# MIMXRT1062 register map
Vendor: nxp.com; File version: 1.0
CPU: CM7 r0p1, little endian, MPU, FPU, VTOR, 4 interrupt priority bits
Registers are 32-bit, read-write, reset 0x0 unless marked. A register's access mark holds for its fields unless they carry their own. Offsets are from the block's base; [hi:lo] are bit positions.

## IOMUXC (part 1 of 4)
Base 0x401F8000; register names take the prefix IOMUXC_
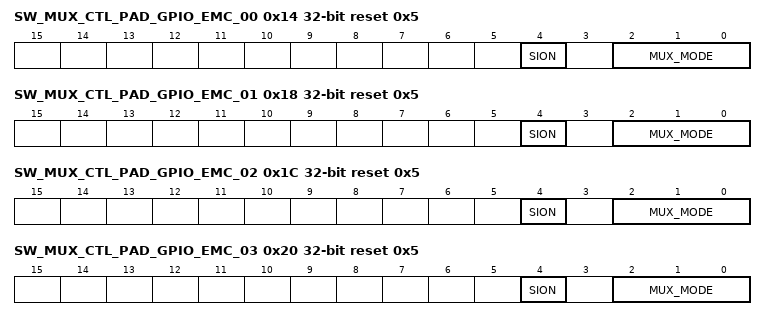
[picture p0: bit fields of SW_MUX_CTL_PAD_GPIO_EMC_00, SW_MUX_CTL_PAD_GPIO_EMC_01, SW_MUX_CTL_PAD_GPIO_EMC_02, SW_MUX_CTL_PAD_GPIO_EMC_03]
0x14 SW_MUX_CTL_PAD_GPIO_EMC_00 reset 0x5 — SW_MUX_CTL_PAD_GPIO_EMC_00 SW MUX Control Register
  [4] SION — Software Input On Field.
    0=DISABLED (Input Path is determined by functionality); 1=ENABLED (Force input path of pad GPIO_EMC_00)
  [2:0] MUX_MODE — MUX Mode Select Field.
    0=ALT0 (Select mux mode: ALT0 mux port: SEMC_DATA00 of instance: semc); 1=ALT1 (Select mux mode: ALT1 mux port: FLEXPWM4_PWMA00 of instance: flexpwm4); 2=ALT2 (Select mux mode: ALT2 mux port: LPSPI2_SCK of instance: lpspi2); 3=ALT3 (Select mux mode: ALT3 mux port: XBAR1_XBAR_IN02 of instance: xbar1); 4=ALT4 (Select mux mode: ALT4 mux port: FLEXIO1_FLEXIO00 of instance: flexio1); 5=ALT5 (Select mux mode: ALT5 mux port: GPIO4_IO00 of instance: gpio4)
0x18 SW_MUX_CTL_PAD_GPIO_EMC_01 reset 0x5 — SW_MUX_CTL_PAD_GPIO_EMC_01 SW MUX Control Register
  [4] SION — Software Input On Field.
    0=DISABLED (Input Path is determined by functionality); 1=ENABLED (Force input path of pad GPIO_EMC_01)
  [2:0] MUX_MODE — MUX Mode Select Field.
    0=ALT0 (Select mux mode: ALT0 mux port: SEMC_DATA01 of instance: semc); 1=ALT1 (Select mux mode: ALT1 mux port: FLEXPWM4_PWMB00 of instance: flexpwm4); 2=ALT2 (Select mux mode: ALT2 mux port: LPSPI2_PCS0 of instance: lpspi2); 3=ALT3 (Select mux mode: ALT3 mux port: XBAR1_IN03 of instance: xbar1); 4=ALT4 (Select mux mode: ALT4 mux port: FLEXIO1_FLEXIO01 of instance: flexio1); 5=ALT5 (Select mux mode: ALT5 mux port: GPIO4_IO01 of instance: gpio4)
0x1C SW_MUX_CTL_PAD_GPIO_EMC_02 reset 0x5 — SW_MUX_CTL_PAD_GPIO_EMC_02 SW MUX Control Register
  [4] SION — Software Input On Field.
    0=DISABLED (Input Path is determined by functionality); 1=ENABLED (Force input path of pad GPIO_EMC_02)
  [2:0] MUX_MODE — MUX Mode Select Field.
    0=ALT0 (Select mux mode: ALT0 mux port: SEMC_DATA02 of instance: semc); 1=ALT1 (Select mux mode: ALT1 mux port: FLEXPWM4_PWMA01 of instance: flexpwm4); 2=ALT2 (Select mux mode: ALT2 mux port: LPSPI2_SDO of instance: lpspi2); 3=ALT3 (Select mux mode: ALT3 mux port: XBAR1_INOUT04 of instance: xbar1); 4=ALT4 (Select mux mode: ALT4 mux port: FLEXIO1_FLEXIO02 of instance: flexio1); 5=ALT5 (Select mux mode: ALT5 mux port: GPIO4_IO02 of instance: gpio4)
0x20 SW_MUX_CTL_PAD_GPIO_EMC_03 reset 0x5 — SW_MUX_CTL_PAD_GPIO_EMC_03 SW MUX Control Register
  [4] SION — Software Input On Field.
    0=DISABLED (Input Path is determined by functionality); 1=ENABLED (Force input path of pad GPIO_EMC_03)
  [2:0] MUX_MODE — MUX Mode Select Field.
    0=ALT0 (Select mux mode: ALT0 mux port: SEMC_DATA03 of instance: semc); 1=ALT1 (Select mux mode: ALT1 mux port: FLEXPWM4_PWMB01 of instance: flexpwm4); 2=ALT2 (Select mux mode: ALT2 mux port: LPSPI2_SDI of instance: lpspi2); 3=ALT3 (Select mux mode: ALT3 mux port: XBAR1_INOUT05 of instance: xbar1); 4=ALT4 (Select mux mode: ALT4 mux port: FLEXIO1_FLEXIO03 of instance: flexio1); 5=ALT5 (Select mux mode: ALT5 mux port: GPIO4_IO03 of instance: gpio4)
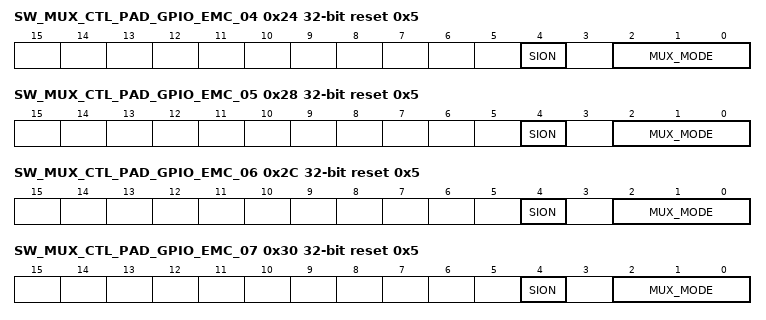
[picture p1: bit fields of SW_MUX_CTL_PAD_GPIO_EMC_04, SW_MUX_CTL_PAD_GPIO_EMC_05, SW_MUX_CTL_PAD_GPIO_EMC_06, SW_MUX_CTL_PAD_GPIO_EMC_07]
0x24 SW_MUX_CTL_PAD_GPIO_EMC_04 reset 0x5 — SW_MUX_CTL_PAD_GPIO_EMC_04 SW MUX Control Register
  [4] SION — Software Input On Field.
    0=DISABLED (Input Path is determined by functionality); 1=ENABLED (Force input path of pad GPIO_EMC_04)
  [2:0] MUX_MODE — MUX Mode Select Field.
    0=ALT0 (Select mux mode: ALT0 mux port: SEMC_DATA04 of instance: semc); 1=ALT1 (Select mux mode: ALT1 mux port: FLEXPWM4_PWMA02 of instance: flexpwm4); 2=ALT2 (Select mux mode: ALT2 mux port: SAI2_TX_DATA of instance: sai2); 3=ALT3 (Select mux mode: ALT3 mux port: XBAR1_INOUT06 of instance: xbar1); 4=ALT4 (Select mux mode: ALT4 mux port: FLEXIO1_FLEXIO04 of instance: flexio1); 5=ALT5 (Select mux mode: ALT5 mux port: GPIO4_IO04 of instance: gpio4)
0x28 SW_MUX_CTL_PAD_GPIO_EMC_05 reset 0x5 — SW_MUX_CTL_PAD_GPIO_EMC_05 SW MUX Control Register
  [4] SION — Software Input On Field.
    0=DISABLED (Input Path is determined by functionality); 1=ENABLED (Force input path of pad GPIO_EMC_05)
  [2:0] MUX_MODE — MUX Mode Select Field.
    0=ALT0 (Select mux mode: ALT0 mux port: SEMC_DATA05 of instance: semc); 1=ALT1 (Select mux mode: ALT1 mux port: FLEXPWM4_PWMB02 of instance: flexpwm4); 2=ALT2 (Select mux mode: ALT2 mux port: SAI2_TX_SYNC of instance: sai2); 3=ALT3 (Select mux mode: ALT3 mux port: XBAR1_INOUT07 of instance: xbar1); 4=ALT4 (Select mux mode: ALT4 mux port: FLEXIO1_FLEXIO05 of instance: flexio1); 5=ALT5 (Select mux mode: ALT5 mux port: GPIO4_IO05 of instance: gpio4)
0x2C SW_MUX_CTL_PAD_GPIO_EMC_06 reset 0x5 — SW_MUX_CTL_PAD_GPIO_EMC_06 SW MUX Control Register
  [4] SION — Software Input On Field.
    0=DISABLED (Input Path is determined by functionality); 1=ENABLED (Force input path of pad GPIO_EMC_06)
  [2:0] MUX_MODE — MUX Mode Select Field.
    0=ALT0 (Select mux mode: ALT0 mux port: SEMC_DATA06 of instance: semc); 1=ALT1 (Select mux mode: ALT1 mux port: FLEXPWM2_PWMA00 of instance: flexpwm2); 2=ALT2 (Select mux mode: ALT2 mux port: SAI2_TX_BCLK of instance: sai2); 3=ALT3 (Select mux mode: ALT3 mux port: XBAR1_INOUT08 of instance: xbar1); 4=ALT4 (Select mux mode: ALT4 mux port: FLEXIO1_FLEXIO06 of instance: flexio1); 5=ALT5 (Select mux mode: ALT5 mux port: GPIO4_IO06 of instance: gpio4)
0x30 SW_MUX_CTL_PAD_GPIO_EMC_07 reset 0x5 — SW_MUX_CTL_PAD_GPIO_EMC_07 SW MUX Control Register
  [4] SION — Software Input On Field.
    0=DISABLED (Input Path is determined by functionality); 1=ENABLED (Force input path of pad GPIO_EMC_07)
  [2:0] MUX_MODE — MUX Mode Select Field.
    0=ALT0 (Select mux mode: ALT0 mux port: SEMC_DATA07 of instance: semc); 1=ALT1 (Select mux mode: ALT1 mux port: FLEXPWM2_PWMB00 of instance: flexpwm2); 2=ALT2 (Select mux mode: ALT2 mux port: SAI2_MCLK of instance: sai2); 3=ALT3 (Select mux mode: ALT3 mux port: XBAR1_INOUT09 of instance: xbar1); 4=ALT4 (Select mux mode: ALT4 mux port: FLEXIO1_FLEXIO07 of instance: flexio1); 5=ALT5 (Select mux mode: ALT5 mux port: GPIO4_IO07 of instance: gpio4)
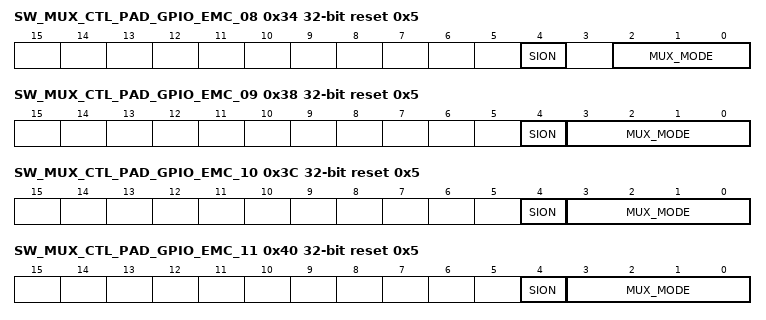
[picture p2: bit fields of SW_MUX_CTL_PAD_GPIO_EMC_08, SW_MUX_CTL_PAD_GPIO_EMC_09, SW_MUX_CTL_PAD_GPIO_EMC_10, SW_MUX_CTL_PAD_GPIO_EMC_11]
0x34 SW_MUX_CTL_PAD_GPIO_EMC_08 reset 0x5 — SW_MUX_CTL_PAD_GPIO_EMC_08 SW MUX Control Register
  [4] SION — Software Input On Field.
    0=DISABLED (Input Path is determined by functionality); 1=ENABLED (Force input path of pad GPIO_EMC_08)
  [2:0] MUX_MODE — MUX Mode Select Field.
    0=ALT0 (Select mux mode: ALT0 mux port: SEMC_DM00 of instance: semc); 1=ALT1 (Select mux mode: ALT1 mux port: FLEXPWM2_PWMA01 of instance: flexpwm2); 2=ALT2 (Select mux mode: ALT2 mux port: SAI2_RX_DATA of instance: sai2); 3=ALT3 (Select mux mode: ALT3 mux port: XBAR1_INOUT17 of instance: xbar1); 4=ALT4 (Select mux mode: ALT4 mux port: FLEXIO1_FLEXIO08 of instance: flexio1); 5=ALT5 (Select mux mode: ALT5 mux port: GPIO4_IO08 of instance: gpio4)
0x38 SW_MUX_CTL_PAD_GPIO_EMC_09 reset 0x5 — SW_MUX_CTL_PAD_GPIO_EMC_09 SW MUX Control Register
  [4] SION — Software Input On Field.
    0=DISABLED (Input Path is determined by functionality); 1=ENABLED (Force input path of pad GPIO_EMC_09)
  [3:0] MUX_MODE — MUX Mode Select Field.
    0=ALT0 (Select mux mode: ALT0 mux port: SEMC_ADDR00 of instance: semc); 1=ALT1 (Select mux mode: ALT1 mux port: FLEXPWM2_PWMB01 of instance: flexpwm2); 2=ALT2 (Select mux mode: ALT2 mux port: SAI2_RX_SYNC of instance: sai2); 3=ALT3 (Select mux mode: ALT3 mux port: FLEXCAN2_TX of instance: flexcan2); 4=ALT4 (Select mux mode: ALT4 mux port: FLEXIO1_FLEXIO09 of instance: flexio1); 5=ALT5 (Select mux mode: ALT5 mux port: GPIO4_IO09 of instance: gpio4); 8=ALT8 (Select mux mode: ALT8 mux port: FLEXSPI2_B_SS1_B of instance: flexspi2)
0x3C SW_MUX_CTL_PAD_GPIO_EMC_10 reset 0x5 — SW_MUX_CTL_PAD_GPIO_EMC_10 SW MUX Control Register
  [4] SION — Software Input On Field.
    0=DISABLED (Input Path is determined by functionality); 1=ENABLED (Force input path of pad GPIO_EMC_10)
  [3:0] MUX_MODE — MUX Mode Select Field.
    0=ALT0 (Select mux mode: ALT0 mux port: SEMC_ADDR01 of instance: semc); 1=ALT1 (Select mux mode: ALT1 mux port: FLEXPWM2_PWMA02 of instance: flexpwm2); 2=ALT2 (Select mux mode: ALT2 mux port: SAI2_RX_BCLK of instance: sai2); 3=ALT3 (Select mux mode: ALT3 mux port: FLEXCAN2_RX of instance: flexcan2); 4=ALT4 (Select mux mode: ALT4 mux port: FLEXIO1_FLEXIO10 of instance: flexio1); 5=ALT5 (Select mux mode: ALT5 mux port: GPIO4_IO10 of instance: gpio4); 8=ALT8 (Select mux mode: ALT8 mux port: FLEXSPI2_B_SS0_B of instance: flexspi2)
0x40 SW_MUX_CTL_PAD_GPIO_EMC_11 reset 0x5 — SW_MUX_CTL_PAD_GPIO_EMC_11 SW MUX Control Register
  [4] SION — Software Input On Field.
    0=DISABLED (Input Path is determined by functionality); 1=ENABLED (Force input path of pad GPIO_EMC_11)
  [3:0] MUX_MODE — MUX Mode Select Field.
    0=ALT0 (Select mux mode: ALT0 mux port: SEMC_ADDR02 of instance: semc); 1=ALT1 (Select mux mode: ALT1 mux port: FLEXPWM2_PWMB02 of instance: flexpwm2); 2=ALT2 (Select mux mode: ALT2 mux port: LPI2C4_SDA of instance: lpi2c4); 3=ALT3 (Select mux mode: ALT3 mux port: USDHC2_RESET_B of instance: usdhc2); 4=ALT4 (Select mux mode: ALT4 mux port: FLEXIO1_FLEXIO11 of instance: flexio1); 5=ALT5 (Select mux mode: ALT5 mux port: GPIO4_IO11 of instance: gpio4); 8=ALT8 (Select mux mode: ALT8 mux port: FLEXSPI2_B_DQS of instance: flexspi2)
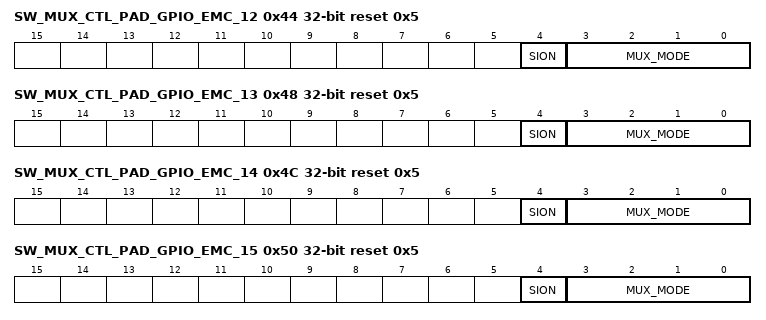
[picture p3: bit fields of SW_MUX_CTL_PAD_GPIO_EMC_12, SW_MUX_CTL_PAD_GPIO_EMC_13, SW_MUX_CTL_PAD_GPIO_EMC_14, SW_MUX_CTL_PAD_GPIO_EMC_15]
0x44 SW_MUX_CTL_PAD_GPIO_EMC_12 reset 0x5 — SW_MUX_CTL_PAD_GPIO_EMC_12 SW MUX Control Register
  [4] SION — Software Input On Field.
    0=DISABLED (Input Path is determined by functionality); 1=ENABLED (Force input path of pad GPIO_EMC_12)
  [3:0] MUX_MODE — MUX Mode Select Field.
    0=ALT0 (Select mux mode: ALT0 mux port: SEMC_ADDR03 of instance: semc); 1=ALT1 (Select mux mode: ALT1 mux port: XBAR1_IN24 of instance: xbar1); 2=ALT2 (Select mux mode: ALT2 mux port: LPI2C4_SCL of instance: lpi2c4); 3=ALT3 (Select mux mode: ALT3 mux port: USDHC1_WP of instance: usdhc1); 4=ALT4 (Select mux mode: ALT4 mux port: FLEXPWM1_PWMA03 of instance: flexpwm1); 5=ALT5 (Select mux mode: ALT5 mux port: GPIO4_IO12 of instance: gpio4); 8=ALT8 (Select mux mode: ALT8 mux port: FLEXSPI2_B_SCLK of instance: flexspi2)
0x48 SW_MUX_CTL_PAD_GPIO_EMC_13 reset 0x5 — SW_MUX_CTL_PAD_GPIO_EMC_13 SW MUX Control Register
  [4] SION — Software Input On Field.
    0=DISABLED (Input Path is determined by functionality); 1=ENABLED (Force input path of pad GPIO_EMC_13)
  [3:0] MUX_MODE — MUX Mode Select Field.
    0=ALT0 (Select mux mode: ALT0 mux port: SEMC_ADDR04 of instance: semc); 1=ALT1 (Select mux mode: ALT1 mux port: XBAR1_IN25 of instance: xbar1); 2=ALT2 (Select mux mode: ALT2 mux port: LPUART3_TX of instance: lpuart3); 3=ALT3 (Select mux mode: ALT3 mux port: MQS_RIGHT of instance: mqs); 4=ALT4 (Select mux mode: ALT4 mux port: FLEXPWM1_PWMB03 of instance: flexpwm1); 5=ALT5 (Select mux mode: ALT5 mux port: GPIO4_IO13 of instance: gpio4); 8=ALT8 (Select mux mode: ALT8 mux port: FLEXSPI2_B_DATA00 of instance: flexspi2)
0x4C SW_MUX_CTL_PAD_GPIO_EMC_14 reset 0x5 — SW_MUX_CTL_PAD_GPIO_EMC_14 SW MUX Control Register
  [4] SION — Software Input On Field.
    0=DISABLED (Input Path is determined by functionality); 1=ENABLED (Force input path of pad GPIO_EMC_14)
  [3:0] MUX_MODE — MUX Mode Select Field.
    0=ALT0 (Select mux mode: ALT0 mux port: SEMC_ADDR05 of instance: semc); 1=ALT1 (Select mux mode: ALT1 mux port: XBAR1_INOUT19 of instance: xbar1); 2=ALT2 (Select mux mode: ALT2 mux port: LPUART3_RX of instance: lpuart3); 3=ALT3 (Select mux mode: ALT3 mux port: MQS_LEFT of instance: mqs); 4=ALT4 (Select mux mode: ALT4 mux port: LPSPI2_PCS1 of instance: lpspi2); 5=ALT5 (Select mux mode: ALT5 mux port: GPIO4_IO14 of instance: gpio4); 8=ALT8 (Select mux mode: ALT8 mux port: FLEXSPI2_B_DATA01 of instance: flexspi2)
0x50 SW_MUX_CTL_PAD_GPIO_EMC_15 reset 0x5 — SW_MUX_CTL_PAD_GPIO_EMC_15 SW MUX Control Register
  [4] SION — Software Input On Field.
    0=DISABLED (Input Path is determined by functionality); 1=ENABLED (Force input path of pad GPIO_EMC_15)
  [3:0] MUX_MODE — MUX Mode Select Field.
    0=ALT0 (Select mux mode: ALT0 mux port: SEMC_ADDR06 of instance: semc); 1=ALT1 (Select mux mode: ALT1 mux port: XBAR1_IN20 of instance: xbar1); 2=ALT2 (Select mux mode: ALT2 mux port: LPUART3_CTS_B of instance: lpuart3); 3=ALT3 (Select mux mode: ALT3 mux port: SPDIF_OUT of instance: spdif); 4=ALT4 (Select mux mode: ALT4 mux port: QTIMER3_TIMER0 of instance: qtimer3); 5=ALT5 (Select mux mode: ALT5 mux port: GPIO4_IO15 of instance: gpio4); 8=ALT8 (Select mux mode: ALT8 mux port: FLEXSPI2_B_DATA02 of instance: flexspi2)
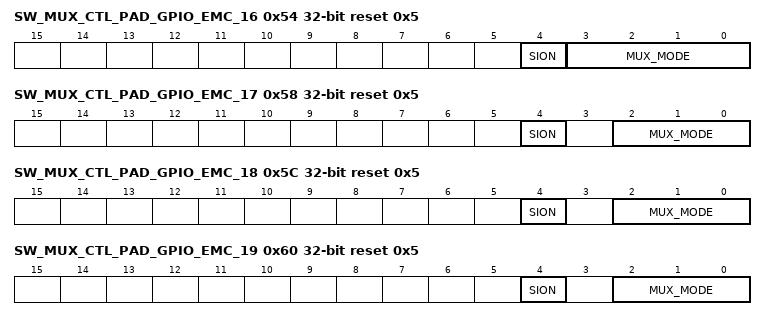
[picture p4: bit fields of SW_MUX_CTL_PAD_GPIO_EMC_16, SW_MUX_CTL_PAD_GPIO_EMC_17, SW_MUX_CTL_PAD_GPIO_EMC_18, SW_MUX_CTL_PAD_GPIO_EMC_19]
0x54 SW_MUX_CTL_PAD_GPIO_EMC_16 reset 0x5 — SW_MUX_CTL_PAD_GPIO_EMC_16 SW MUX Control Register
  [4] SION — Software Input On Field.
    0=DISABLED (Input Path is determined by functionality); 1=ENABLED (Force input path of pad GPIO_EMC_16)
  [3:0] MUX_MODE — MUX Mode Select Field.
    0=ALT0 (Select mux mode: ALT0 mux port: SEMC_ADDR07 of instance: semc); 1=ALT1 (Select mux mode: ALT1 mux port: XBAR1_IN21 of instance: xbar1); 2=ALT2 (Select mux mode: ALT2 mux port: LPUART3_RTS_B of instance: lpuart3); 3=ALT3 (Select mux mode: ALT3 mux port: SPDIF_IN of instance: spdif); 4=ALT4 (Select mux mode: ALT4 mux port: QTIMER3_TIMER1 of instance: qtimer3); 5=ALT5 (Select mux mode: ALT5 mux port: GPIO4_IO16 of instance: gpio4); 8=ALT8 (Select mux mode: ALT8 mux port: FLEXSPI2_B_DATA03 of instance: flexspi2)
0x58 SW_MUX_CTL_PAD_GPIO_EMC_17 reset 0x5 — SW_MUX_CTL_PAD_GPIO_EMC_17 SW MUX Control Register
  [4] SION — Software Input On Field.
    0=DISABLED (Input Path is determined by functionality); 1=ENABLED (Force input path of pad GPIO_EMC_17)
  [2:0] MUX_MODE — MUX Mode Select Field.
    0=ALT0 (Select mux mode: ALT0 mux port: SEMC_ADDR08 of instance: semc); 1=ALT1 (Select mux mode: ALT1 mux port: FLEXPWM4_PWMA03 of instance: flexpwm4); 2=ALT2 (Select mux mode: ALT2 mux port: LPUART4_CTS_B of instance: lpuart4); 3=ALT3 (Select mux mode: ALT3 mux port: FLEXCAN1_TX of instance: flexcan1); 4=ALT4 (Select mux mode: ALT4 mux port: QTIMER3_TIMER2 of instance: qtimer3); 5=ALT5 (Select mux mode: ALT5 mux port: GPIO4_IO17 of instance: gpio4)
0x5C SW_MUX_CTL_PAD_GPIO_EMC_18 reset 0x5 — SW_MUX_CTL_PAD_GPIO_EMC_18 SW MUX Control Register
  [4] SION — Software Input On Field.
    0=DISABLED (Input Path is determined by functionality); 1=ENABLED (Force input path of pad GPIO_EMC_18)
  [2:0] MUX_MODE — MUX Mode Select Field.
    0=ALT0 (Select mux mode: ALT0 mux port: SEMC_ADDR09 of instance: semc); 1=ALT1 (Select mux mode: ALT1 mux port: FLEXPWM4_PWMB03 of instance: flexpwm4); 2=ALT2 (Select mux mode: ALT2 mux port: LPUART4_RTS_B of instance: lpuart4); 3=ALT3 (Select mux mode: ALT3 mux port: FLEXCAN1_RX of instance: flexcan1); 4=ALT4 (Select mux mode: ALT4 mux port: QTIMER3_TIMER3 of instance: qtimer3); 5=ALT5 (Select mux mode: ALT5 mux port: GPIO4_IO18 of instance: gpio4); 6=ALT6 (Select mux mode: ALT6 mux port: SNVS_VIO_5_CTL of instance: snvs_hp)
0x60 SW_MUX_CTL_PAD_GPIO_EMC_19 reset 0x5 — SW_MUX_CTL_PAD_GPIO_EMC_19 SW MUX Control Register
  [4] SION — Software Input On Field.
    0=DISABLED (Input Path is determined by functionality); 1=ENABLED (Force input path of pad GPIO_EMC_19)
  [2:0] MUX_MODE — MUX Mode Select Field.
    0=ALT0 (Select mux mode: ALT0 mux port: SEMC_ADDR11 of instance: semc); 1=ALT1 (Select mux mode: ALT1 mux port: FLEXPWM2_PWMA03 of instance: flexpwm2); 2=ALT2 (Select mux mode: ALT2 mux port: LPUART4_TX of instance: lpuart4); 3=ALT3 (Select mux mode: ALT3 mux port: ENET_RDATA01 of instance: enet); 4=ALT4 (Select mux mode: ALT4 mux port: QTIMER2_TIMER0 of instance: qtimer2); 5=ALT5 (Select mux mode: ALT5 mux port: GPIO4_IO19 of instance: gpio4); 6=ALT6 (Select mux mode: ALT6 mux port: SNVS_VIO_5 of instance: snvs_hp)
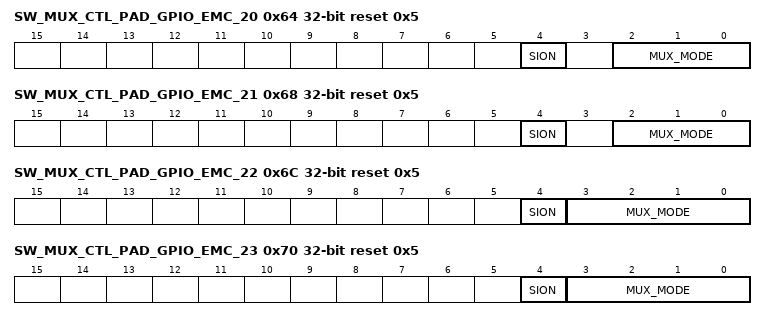
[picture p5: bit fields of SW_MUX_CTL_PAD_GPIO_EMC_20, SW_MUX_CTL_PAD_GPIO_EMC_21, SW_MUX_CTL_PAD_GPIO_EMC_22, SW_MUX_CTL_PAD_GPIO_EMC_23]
0x64 SW_MUX_CTL_PAD_GPIO_EMC_20 reset 0x5 — SW_MUX_CTL_PAD_GPIO_EMC_20 SW MUX Control Register
  [4] SION — Software Input On Field.
    0=DISABLED (Input Path is determined by functionality); 1=ENABLED (Force input path of pad GPIO_EMC_20)
  [2:0] MUX_MODE — MUX Mode Select Field.
    0=ALT0 (Select mux mode: ALT0 mux port: SEMC_ADDR12 of instance: semc); 1=ALT1 (Select mux mode: ALT1 mux port: FLEXPWM2_PWMB03 of instance: flexpwm2); 2=ALT2 (Select mux mode: ALT2 mux port: LPUART4_RX of instance: lpuart4); 3=ALT3 (Select mux mode: ALT3 mux port: ENET_RDATA00 of instance: enet); 4=ALT4 (Select mux mode: ALT4 mux port: QTIMER2_TIMER1 of instance: qtimer2); 5=ALT5 (Select mux mode: ALT5 mux port: GPIO4_IO20 of instance: gpio4)
0x68 SW_MUX_CTL_PAD_GPIO_EMC_21 reset 0x5 — SW_MUX_CTL_PAD_GPIO_EMC_21 SW MUX Control Register
  [4] SION — Software Input On Field.
    0=DISABLED (Input Path is determined by functionality); 1=ENABLED (Force input path of pad GPIO_EMC_21)
  [2:0] MUX_MODE — MUX Mode Select Field.
    0=ALT0 (Select mux mode: ALT0 mux port: SEMC_BA0 of instance: semc); 1=ALT1 (Select mux mode: ALT1 mux port: FLEXPWM3_PWMA03 of instance: flexpwm3); 2=ALT2 (Select mux mode: ALT2 mux port: LPI2C3_SDA of instance: lpi2c3); 3=ALT3 (Select mux mode: ALT3 mux port: ENET_TDATA01 of instance: enet); 4=ALT4 (Select mux mode: ALT4 mux port: QTIMER2_TIMER2 of instance: qtimer2); 5=ALT5 (Select mux mode: ALT5 mux port: GPIO4_IO21 of instance: gpio4)
0x6C SW_MUX_CTL_PAD_GPIO_EMC_22 reset 0x5 — SW_MUX_CTL_PAD_GPIO_EMC_22 SW MUX Control Register
  [4] SION — Software Input On Field.
    0=DISABLED (Input Path is determined by functionality); 1=ENABLED (Force input path of pad GPIO_EMC_22)
  [3:0] MUX_MODE — MUX Mode Select Field.
    0=ALT0 (Select mux mode: ALT0 mux port: SEMC_BA1 of instance: semc); 1=ALT1 (Select mux mode: ALT1 mux port: FLEXPWM3_PWMB03 of instance: flexpwm3); 2=ALT2 (Select mux mode: ALT2 mux port: LPI2C3_SCL of instance: lpi2c3); 3=ALT3 (Select mux mode: ALT3 mux port: ENET_TDATA00 of instance: enet); 4=ALT4 (Select mux mode: ALT4 mux port: QTIMER2_TIMER3 of instance: qtimer2); 5=ALT5 (Select mux mode: ALT5 mux port: GPIO4_IO22 of instance: gpio4); 8=ALT8 (Select mux mode: ALT8 mux port: FLEXSPI2_A_SS1_B of instance: flexspi2)
0x70 SW_MUX_CTL_PAD_GPIO_EMC_23 reset 0x5 — SW_MUX_CTL_PAD_GPIO_EMC_23 SW MUX Control Register
  [4] SION — Software Input On Field.
    0=DISABLED (Input Path is determined by functionality); 1=ENABLED (Force input path of pad GPIO_EMC_23)
  [3:0] MUX_MODE — MUX Mode Select Field.
    0=ALT0 (Select mux mode: ALT0 mux port: SEMC_ADDR10 of instance: semc); 1=ALT1 (Select mux mode: ALT1 mux port: FLEXPWM1_PWMA00 of instance: flexpwm1); 2=ALT2 (Select mux mode: ALT2 mux port: LPUART5_TX of instance: lpuart5); 3=ALT3 (Select mux mode: ALT3 mux port: ENET_RX_EN of instance: enet); 4=ALT4 (Select mux mode: ALT4 mux port: GPT1_CAPTURE2 of instance: gpt1); 5=ALT5 (Select mux mode: ALT5 mux port: GPIO4_IO23 of instance: gpio4); 8=ALT8 (Select mux mode: ALT8 mux port: FLEXSPI2_A_DQS of instance: flexspi2)
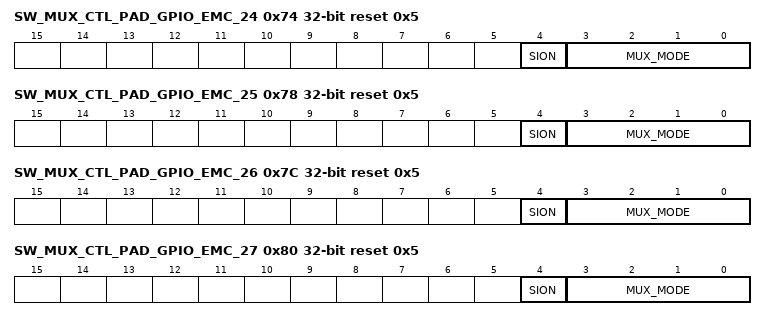
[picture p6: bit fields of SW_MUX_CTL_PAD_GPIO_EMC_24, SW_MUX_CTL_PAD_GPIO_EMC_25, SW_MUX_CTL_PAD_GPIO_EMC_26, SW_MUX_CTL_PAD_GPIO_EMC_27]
0x74 SW_MUX_CTL_PAD_GPIO_EMC_24 reset 0x5 — SW_MUX_CTL_PAD_GPIO_EMC_24 SW MUX Control Register
  [4] SION — Software Input On Field.
    0=DISABLED (Input Path is determined by functionality); 1=ENABLED (Force input path of pad GPIO_EMC_24)
  [3:0] MUX_MODE — MUX Mode Select Field.
    0=ALT0 (Select mux mode: ALT0 mux port: SEMC_CAS of instance: semc); 1=ALT1 (Select mux mode: ALT1 mux port: FLEXPWM1_PWMB00 of instance: flexpwm1); 2=ALT2 (Select mux mode: ALT2 mux port: LPUART5_RX of instance: lpuart5); 3=ALT3 (Select mux mode: ALT3 mux port: ENET_TX_EN of instance: enet); 4=ALT4 (Select mux mode: ALT4 mux port: GPT1_CAPTURE1 of instance: gpt1); 5=ALT5 (Select mux mode: ALT5 mux port: GPIO4_IO24 of instance: gpio4); 8=ALT8 (Select mux mode: ALT8 mux port: FLEXSPI2_A_SS0_B of instance: flexspi2)
0x78 SW_MUX_CTL_PAD_GPIO_EMC_25 reset 0x5 — SW_MUX_CTL_PAD_GPIO_EMC_25 SW MUX Control Register
  [4] SION — Software Input On Field.
    0=DISABLED (Input Path is determined by functionality); 1=ENABLED (Force input path of pad GPIO_EMC_25)
  [3:0] MUX_MODE — MUX Mode Select Field.
    0=ALT0 (Select mux mode: ALT0 mux port: SEMC_RAS of instance: semc); 1=ALT1 (Select mux mode: ALT1 mux port: FLEXPWM1_PWMA01 of instance: flexpwm1); 2=ALT2 (Select mux mode: ALT2 mux port: LPUART6_TX of instance: lpuart6); 3=ALT3 (Select mux mode: ALT3 mux port: ENET_TX_CLK of instance: enet); 4=ALT4 (Select mux mode: ALT4 mux port: ENET_REF_CLK of instance: enet); 5=ALT5 (Select mux mode: ALT5 mux port: GPIO4_IO25 of instance: gpio4); 8=ALT8 (Select mux mode: ALT8 mux port: FLEXSPI2_A_SCLK of instance: flexspi2)
0x7C SW_MUX_CTL_PAD_GPIO_EMC_26 reset 0x5 — SW_MUX_CTL_PAD_GPIO_EMC_26 SW MUX Control Register
  [4] SION — Software Input On Field.
    0=DISABLED (Input Path is determined by functionality); 1=ENABLED (Force input path of pad GPIO_EMC_26)
  [3:0] MUX_MODE — MUX Mode Select Field.
    0=ALT0 (Select mux mode: ALT0 mux port: SEMC_CLK of instance: semc); 1=ALT1 (Select mux mode: ALT1 mux port: FLEXPWM1_PWMB01 of instance: flexpwm1); 2=ALT2 (Select mux mode: ALT2 mux port: LPUART6_RX of instance: lpuart6); 3=ALT3 (Select mux mode: ALT3 mux port: ENET_RX_ER of instance: enet); 4=ALT4 (Select mux mode: ALT4 mux port: FLEXIO1_FLEXIO12 of instance: flexio1); 5=ALT5 (Select mux mode: ALT5 mux port: GPIO4_IO26 of instance: gpio4); 8=ALT8 (Select mux mode: ALT8 mux port: FLEXSPI2_A_DATA00 of instance: flexspi2)
0x80 SW_MUX_CTL_PAD_GPIO_EMC_27 reset 0x5 — SW_MUX_CTL_PAD_GPIO_EMC_27 SW MUX Control Register
  [4] SION — Software Input On Field.
    0=DISABLED (Input Path is determined by functionality); 1=ENABLED (Force input path of pad GPIO_EMC_27)
  [3:0] MUX_MODE — MUX Mode Select Field.
    0=ALT0 (Select mux mode: ALT0 mux port: SEMC_CKE of instance: semc); 1=ALT1 (Select mux mode: ALT1 mux port: FLEXPWM1_PWMA02 of instance: flexpwm1); 2=ALT2 (Select mux mode: ALT2 mux port: LPUART5_RTS_B of instance: lpuart5); 3=ALT3 (Select mux mode: ALT3 mux port: LPSPI1_SCK of instance: lpspi1); 4=ALT4 (Select mux mode: ALT4 mux port: FLEXIO1_FLEXIO13 of instance: flexio1); 5=ALT5 (Select mux mode: ALT5 mux port: GPIO4_IO27 of instance: gpio4); 8=ALT8 (Select mux mode: ALT8 mux port: FLEXSPI2_A_DATA01 of instance: flexspi2)
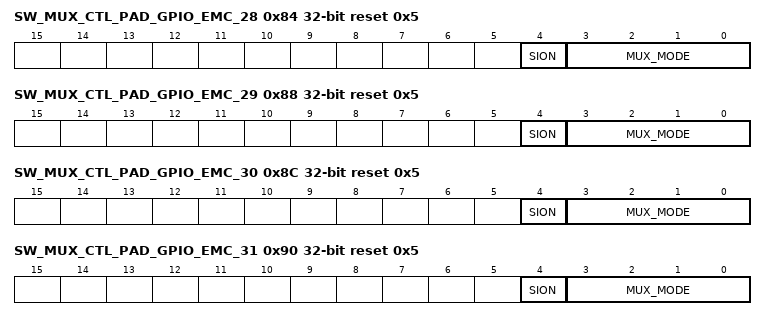
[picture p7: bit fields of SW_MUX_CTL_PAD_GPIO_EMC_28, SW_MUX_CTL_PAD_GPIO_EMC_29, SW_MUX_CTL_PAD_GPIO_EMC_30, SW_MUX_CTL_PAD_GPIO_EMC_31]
0x84 SW_MUX_CTL_PAD_GPIO_EMC_28 reset 0x5 — SW_MUX_CTL_PAD_GPIO_EMC_28 SW MUX Control Register
  [4] SION — Software Input On Field.
    0=DISABLED (Input Path is determined by functionality); 1=ENABLED (Force input path of pad GPIO_EMC_28)
  [3:0] MUX_MODE — MUX Mode Select Field.
    0=ALT0 (Select mux mode: ALT0 mux port: SEMC_WE of instance: semc); 1=ALT1 (Select mux mode: ALT1 mux port: FLEXPWM1_PWMB02 of instance: flexpwm1); 2=ALT2 (Select mux mode: ALT2 mux port: LPUART5_CTS_B of instance: lpuart5); 3=ALT3 (Select mux mode: ALT3 mux port: LPSPI1_SDO of instance: lpspi1); 4=ALT4 (Select mux mode: ALT4 mux port: FLEXIO1_FLEXIO14 of instance: flexio1); 5=ALT5 (Select mux mode: ALT5 mux port: GPIO4_IO28 of instance: gpio4); 8=ALT8 (Select mux mode: ALT8 mux port: FLEXSPI2_A_DATA02 of instance: flexspi2)
0x88 SW_MUX_CTL_PAD_GPIO_EMC_29 reset 0x5 — SW_MUX_CTL_PAD_GPIO_EMC_29 SW MUX Control Register
  [4] SION — Software Input On Field.
    0=DISABLED (Input Path is determined by functionality); 1=ENABLED (Force input path of pad GPIO_EMC_29)
  [3:0] MUX_MODE — MUX Mode Select Field.
    0=ALT0 (Select mux mode: ALT0 mux port: SEMC_CS0 of instance: semc); 1=ALT1 (Select mux mode: ALT1 mux port: FLEXPWM3_PWMA00 of instance: flexpwm3); 2=ALT2 (Select mux mode: ALT2 mux port: LPUART6_RTS_B of instance: lpuart6); 3=ALT3 (Select mux mode: ALT3 mux port: LPSPI1_SDI of instance: lpspi1); 4=ALT4 (Select mux mode: ALT4 mux port: FLEXIO1_FLEXIO15 of instance: flexio1); 5=ALT5 (Select mux mode: ALT5 mux port: GPIO4_IO29 of instance: gpio4); 8=ALT8 (Select mux mode: ALT8 mux port: FLEXSPI2_A_DATA03 of instance: flexspi2)
0x8C SW_MUX_CTL_PAD_GPIO_EMC_30 reset 0x5 — SW_MUX_CTL_PAD_GPIO_EMC_30 SW MUX Control Register
  [4] SION — Software Input On Field.
    0=DISABLED (Input Path is determined by functionality); 1=ENABLED (Force input path of pad GPIO_EMC_30)
  [3:0] MUX_MODE — MUX Mode Select Field.
    0=ALT0 (Select mux mode: ALT0 mux port: SEMC_DATA08 of instance: semc); 1=ALT1 (Select mux mode: ALT1 mux port: FLEXPWM3_PWMB00 of instance: flexpwm3); 2=ALT2 (Select mux mode: ALT2 mux port: LPUART6_CTS_B of instance: lpuart6); 3=ALT3 (Select mux mode: ALT3 mux port: LPSPI1_PCS0 of instance: lpspi1); 4=ALT4 (Select mux mode: ALT4 mux port: CSI_DATA23 of instance: csi); 5=ALT5 (Select mux mode: ALT5 mux port: GPIO4_IO30 of instance: gpio4); 8=ALT8 (Select mux mode: ALT8 mux port: ENET2_TDATA00 of instance: enet2)
0x90 SW_MUX_CTL_PAD_GPIO_EMC_31 reset 0x5 — SW_MUX_CTL_PAD_GPIO_EMC_31 SW MUX Control Register
  [4] SION — Software Input On Field.
    0=DISABLED (Input Path is determined by functionality); 1=ENABLED (Force input path of pad GPIO_EMC_31)
  [3:0] MUX_MODE — MUX Mode Select Field.
    0=ALT0 (Select mux mode: ALT0 mux port: SEMC_DATA09 of instance: semc); 1=ALT1 (Select mux mode: ALT1 mux port: FLEXPWM3_PWMA01 of instance: flexpwm3); 2=ALT2 (Select mux mode: ALT2 mux port: LPUART7_TX of instance: lpuart7); 3=ALT3 (Select mux mode: ALT3 mux port: LPSPI1_PCS1 of instance: lpspi1); 4=ALT4 (Select mux mode: ALT4 mux port: CSI_DATA22 of instance: csi); 5=ALT5 (Select mux mode: ALT5 mux port: GPIO4_IO31 of instance: gpio4); 8=ALT8 (Select mux mode: ALT8 mux port: ENET2_TDATA01 of instance: enet2)
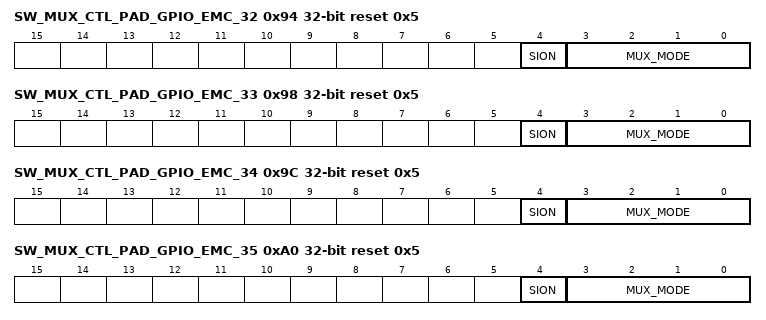
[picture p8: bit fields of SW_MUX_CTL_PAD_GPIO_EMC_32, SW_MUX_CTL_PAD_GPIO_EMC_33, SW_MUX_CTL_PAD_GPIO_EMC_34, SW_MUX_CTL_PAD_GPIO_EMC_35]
0x94 SW_MUX_CTL_PAD_GPIO_EMC_32 reset 0x5 — SW_MUX_CTL_PAD_GPIO_EMC_32 SW MUX Control Register
  [4] SION — Software Input On Field.
    0=DISABLED (Input Path is determined by functionality); 1=ENABLED (Force input path of pad GPIO_EMC_32)
  [3:0] MUX_MODE — MUX Mode Select Field.
    0=ALT0 (Select mux mode: ALT0 mux port: SEMC_DATA10 of instance: semc); 1=ALT1 (Select mux mode: ALT1 mux port: FLEXPWM3_PWMB01 of instance: flexpwm3); 2=ALT2 (Select mux mode: ALT2 mux port: LPUART7_RX of instance: lpuart7); 3=ALT3 (Select mux mode: ALT3 mux port: CCM_PMIC_RDY of instance: ccm); 4=ALT4 (Select mux mode: ALT4 mux port: CSI_DATA21 of instance: csi); 5=ALT5 (Select mux mode: ALT5 mux port: GPIO3_IO18 of instance: gpio3); 8=ALT8 (Select mux mode: ALT8 mux port: ENET2_TX_EN of instance: enet2)
0x98 SW_MUX_CTL_PAD_GPIO_EMC_33 reset 0x5 — SW_MUX_CTL_PAD_GPIO_EMC_33 SW MUX Control Register
  [4] SION — Software Input On Field.
    0=DISABLED (Input Path is determined by functionality); 1=ENABLED (Force input path of pad GPIO_EMC_33)
  [3:0] MUX_MODE — MUX Mode Select Field.
    0=ALT0 (Select mux mode: ALT0 mux port: SEMC_DATA11 of instance: semc); 1=ALT1 (Select mux mode: ALT1 mux port: FLEXPWM3_PWMA02 of instance: flexpwm3); 2=ALT2 (Select mux mode: ALT2 mux port: USDHC1_RESET_B of instance: usdhc1); 3=ALT3 (Select mux mode: ALT3 mux port: SAI3_RX_DATA of instance: sai3); 4=ALT4 (Select mux mode: ALT4 mux port: CSI_DATA20 of instance: csi); 5=ALT5 (Select mux mode: ALT5 mux port: GPIO3_IO19 of instance: gpio3); 8=ALT8 (Select mux mode: ALT8 mux port: ENET2_TX_CLK of instance: enet2); 9=ALT9 (Select mux mode: ALT9 mux port: ENET2_REF_CLK2 of instance: enet2)
0x9C SW_MUX_CTL_PAD_GPIO_EMC_34 reset 0x5 — SW_MUX_CTL_PAD_GPIO_EMC_34 SW MUX Control Register
  [4] SION — Software Input On Field.
    0=DISABLED (Input Path is determined by functionality); 1=ENABLED (Force input path of pad GPIO_EMC_34)
  [3:0] MUX_MODE — MUX Mode Select Field.
    0=ALT0 (Select mux mode: ALT0 mux port: SEMC_DATA12 of instance: semc); 1=ALT1 (Select mux mode: ALT1 mux port: FLEXPWM3_PWMB02 of instance: flexpwm3); 2=ALT2 (Select mux mode: ALT2 mux port: USDHC1_VSELECT of instance: usdhc1); 3=ALT3 (Select mux mode: ALT3 mux port: SAI3_RX_SYNC of instance: sai3); 4=ALT4 (Select mux mode: ALT4 mux port: CSI_DATA19 of instance: csi); 5=ALT5 (Select mux mode: ALT5 mux port: GPIO3_IO20 of instance: gpio3); 8=ALT8 (Select mux mode: ALT8 mux port: ENET2_RX_ER of instance: enet2)
0xA0 SW_MUX_CTL_PAD_GPIO_EMC_35 reset 0x5 — SW_MUX_CTL_PAD_GPIO_EMC_35 SW MUX Control Register
  [4] SION — Software Input On Field.
    0=DISABLED (Input Path is determined by functionality); 1=ENABLED (Force input path of pad GPIO_EMC_35)
  [3:0] MUX_MODE — MUX Mode Select Field.
    0=ALT0 (Select mux mode: ALT0 mux port: SEMC_DATA13 of instance: semc); 1=ALT1 (Select mux mode: ALT1 mux port: XBAR1_INOUT18 of instance: xbar1); 2=ALT2 (Select mux mode: ALT2 mux port: GPT1_COMPARE1 of instance: gpt1); 3=ALT3 (Select mux mode: ALT3 mux port: SAI3_RX_BCLK of instance: sai3); 4=ALT4 (Select mux mode: ALT4 mux port: CSI_DATA18 of instance: csi); 5=ALT5 (Select mux mode: ALT5 mux port: GPIO3_IO21 of instance: gpio3); 6=ALT6 (Select mux mode: ALT6 mux port: USDHC1_CD_B of instance: usdhc1); 8=ALT8 (Select mux mode: ALT8 mux port: ENET2_RDATA00 of instance: enet2)
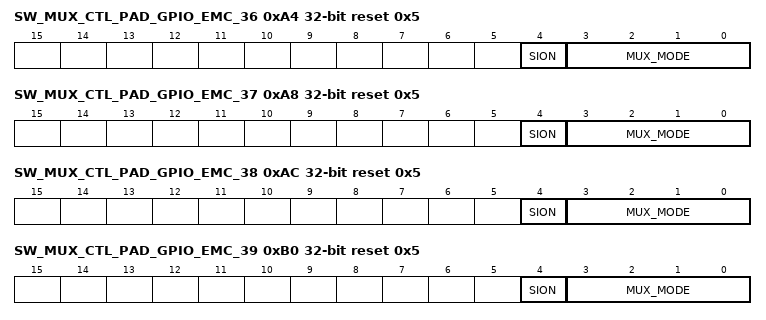
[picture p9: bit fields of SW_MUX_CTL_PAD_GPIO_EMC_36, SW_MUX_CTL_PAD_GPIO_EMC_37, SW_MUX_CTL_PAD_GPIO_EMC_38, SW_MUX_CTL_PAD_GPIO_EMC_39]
0xA4 SW_MUX_CTL_PAD_GPIO_EMC_36 reset 0x5 — SW_MUX_CTL_PAD_GPIO_EMC_36 SW MUX Control Register
  [4] SION — Software Input On Field.
    0=DISABLED (Input Path is determined by functionality); 1=ENABLED (Force input path of pad GPIO_EMC_36)
  [3:0] MUX_MODE — MUX Mode Select Field.
    0=ALT0 (Select mux mode: ALT0 mux port: SEMC_DATA14 of instance: semc); 1=ALT1 (Select mux mode: ALT1 mux port: XBAR1_IN22 of instance: xbar1); 2=ALT2 (Select mux mode: ALT2 mux port: GPT1_COMPARE2 of instance: gpt1); 3=ALT3 (Select mux mode: ALT3 mux port: SAI3_TX_DATA of instance: sai3); 4=ALT4 (Select mux mode: ALT4 mux port: CSI_DATA17 of instance: csi); 5=ALT5 (Select mux mode: ALT5 mux port: GPIO3_IO22 of instance: gpio3); 6=ALT6 (Select mux mode: ALT6 mux port: USDHC1_WP of instance: usdhc1); 8=ALT8 (Select mux mode: ALT8 mux port: ENET2_RDATA01 of instance: enet2); 9=ALT9 (Select mux mode: ALT9 mux port: FLEXCAN3_TX of instance: flexcan3/canfd)
0xA8 SW_MUX_CTL_PAD_GPIO_EMC_37 reset 0x5 — SW_MUX_CTL_PAD_GPIO_EMC_37 SW MUX Control Register
  [4] SION — Software Input On Field.
    0=DISABLED (Input Path is determined by functionality); 1=ENABLED (Force input path of pad GPIO_EMC_37)
  [3:0] MUX_MODE — MUX Mode Select Field.
    0=ALT0 (Select mux mode: ALT0 mux port: SEMC_DATA15 of instance: semc); 1=ALT1 (Select mux mode: ALT1 mux port: XBAR1_IN23 of instance: xbar1); 2=ALT2 (Select mux mode: ALT2 mux port: GPT1_COMPARE3 of instance: gpt1); 3=ALT3 (Select mux mode: ALT3 mux port: SAI3_MCLK of instance: sai3); 4=ALT4 (Select mux mode: ALT4 mux port: CSI_DATA16 of instance: csi); 5=ALT5 (Select mux mode: ALT5 mux port: GPIO3_IO23 of instance: gpio3); 6=ALT6 (Select mux mode: ALT6 mux port: USDHC2_WP of instance: usdhc2); 8=ALT8 (Select mux mode: ALT8 mux port: ENET2_RX_EN of instance: enet2); 9=ALT9 (Select mux mode: ALT9 mux port: FLEXCAN3_RX of instance: flexcan3/canfd)
0xAC SW_MUX_CTL_PAD_GPIO_EMC_38 reset 0x5 — SW_MUX_CTL_PAD_GPIO_EMC_38 SW MUX Control Register
  [4] SION — Software Input On Field.
    0=DISABLED (Input Path is determined by functionality); 1=ENABLED (Force input path of pad GPIO_EMC_38)
  [3:0] MUX_MODE — MUX Mode Select Field.
    0=ALT0 (Select mux mode: ALT0 mux port: SEMC_DM01 of instance: semc); 1=ALT1 (Select mux mode: ALT1 mux port: FLEXPWM1_PWMA03 of instance: flexpwm1); 2=ALT2 (Select mux mode: ALT2 mux port: LPUART8_TX of instance: lpuart8); 3=ALT3 (Select mux mode: ALT3 mux port: SAI3_TX_BCLK of instance: sai3); 4=ALT4 (Select mux mode: ALT4 mux port: CSI_FIELD of instance: csi); 5=ALT5 (Select mux mode: ALT5 mux port: GPIO3_IO24 of instance: gpio3); 6=ALT6 (Select mux mode: ALT6 mux port: USDHC2_VSELECT of instance: usdhc2); 8=ALT8 (Select mux mode: ALT8 mux port: ENET2_MDC of instance: enet2)
0xB0 SW_MUX_CTL_PAD_GPIO_EMC_39 reset 0x5 — SW_MUX_CTL_PAD_GPIO_EMC_39 SW MUX Control Register
  [4] SION — Software Input On Field.
    0=DISABLED (Input Path is determined by functionality); 1=ENABLED (Force input path of pad GPIO_EMC_39)
  [3:0] MUX_MODE — MUX Mode Select Field.
    0=ALT0 (Select mux mode: ALT0 mux port: SEMC_DQS of instance: semc); 1=ALT1 (Select mux mode: ALT1 mux port: FLEXPWM1_PWMB03 of instance: flexpwm1); 2=ALT2 (Select mux mode: ALT2 mux port: LPUART8_RX of instance: lpuart8); 3=ALT3 (Select mux mode: ALT3 mux port: SAI3_TX_SYNC of instance: sai3); 4=ALT4 (Select mux mode: ALT4 mux port: WDOG1_WDOG_B of instance: wdog1); 5=ALT5 (Select mux mode: ALT5 mux port: GPIO3_IO25 of instance: gpio3); 6=ALT6 (Select mux mode: ALT6 mux port: USDHC2_CD_B of instance: usdhc2); 8=ALT8 (Select mux mode: ALT8 mux port: ENET2_MDIO of instance: enet2); 9=ALT9 (Select mux mode: ALT9 mux port: SEMC_DQS4 of instance: semc)
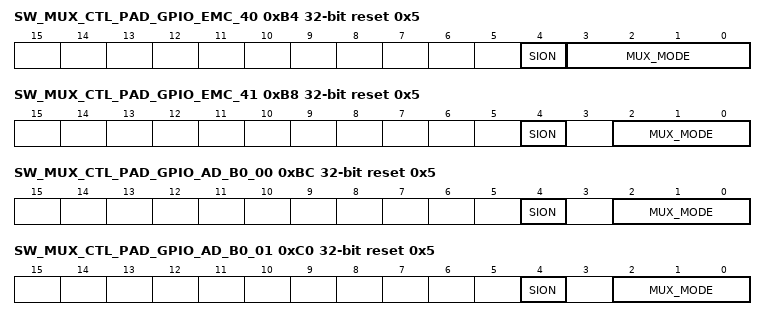
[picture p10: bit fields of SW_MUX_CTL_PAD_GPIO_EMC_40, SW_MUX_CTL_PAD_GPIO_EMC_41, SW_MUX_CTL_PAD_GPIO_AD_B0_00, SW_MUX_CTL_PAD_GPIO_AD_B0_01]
0xB4 SW_MUX_CTL_PAD_GPIO_EMC_40 reset 0x5 — SW_MUX_CTL_PAD_GPIO_EMC_40 SW MUX Control Register
  [4] SION — Software Input On Field.
    0=DISABLED (Input Path is determined by functionality); 1=ENABLED (Force input path of pad GPIO_EMC_40)
  [3:0] MUX_MODE — MUX Mode Select Field.
    0=ALT0 (Select mux mode: ALT0 mux port: SEMC_RDY of instance: semc); 1=ALT1 (Select mux mode: ALT1 mux port: GPT2_CAPTURE2 of instance: gpt2); 2=ALT2 (Select mux mode: ALT2 mux port: LPSPI1_PCS2 of instance: lpspi1); 3=ALT3 (Select mux mode: ALT3 mux port: USB_OTG2_OC of instance: usb); 4=ALT4 (Select mux mode: ALT4 mux port: ENET_MDC of instance: enet); 5=ALT5 (Select mux mode: ALT5 mux port: GPIO3_IO26 of instance: gpio3); 6=ALT6 (Select mux mode: ALT6 mux port: USDHC2_RESET_B of instance: usdhc2); 9=ALT9 (Select mux mode: ALT9 mux port: SEMC_CLK5 of instance: semc)
0xB8 SW_MUX_CTL_PAD_GPIO_EMC_41 reset 0x5 — SW_MUX_CTL_PAD_GPIO_EMC_41 SW MUX Control Register
  [4] SION — Software Input On Field.
    0=DISABLED (Input Path is determined by functionality); 1=ENABLED (Force input path of pad GPIO_EMC_41)
  [2:0] MUX_MODE — MUX Mode Select Field.
    0=ALT0 (Select mux mode: ALT0 mux port: SEMC_CSX00 of instance: semc); 1=ALT1 (Select mux mode: ALT1 mux port: GPT2_CAPTURE1 of instance: gpt2); 2=ALT2 (Select mux mode: ALT2 mux port: LPSPI1_PCS3 of instance: lpspi1); 3=ALT3 (Select mux mode: ALT3 mux port: USB_OTG2_PWR of instance: usb); 4=ALT4 (Select mux mode: ALT4 mux port: ENET_MDIO of instance: enet); 5=ALT5 (Select mux mode: ALT5 mux port: GPIO3_IO27 of instance: gpio3); 6=ALT6 (Select mux mode: ALT6 mux port: USDHC1_VSELECT of instance: usdhc1)
0xBC SW_MUX_CTL_PAD_GPIO_AD_B0_00 reset 0x5 — SW_MUX_CTL_PAD_GPIO_AD_B0_00 SW MUX Control Register
  [4] SION — Software Input On Field.
    0=DISABLED (Input Path is determined by functionality); 1=ENABLED (Force input path of pad GPIO_AD_B0_00)
  [2:0] MUX_MODE — MUX Mode Select Field.
    0=ALT0 (Select mux mode: ALT0 mux port: FLEXPWM2_PWMA03 of instance: flexpwm2); 1=ALT1 (Select mux mode: ALT1 mux port: XBAR1_INOUT14 of instance: xbar1); 2=ALT2 (Select mux mode: ALT2 mux port: REF_CLK_32K of instance: xtalosc); 3=ALT3 (Select mux mode: ALT3 mux port: USB_OTG2_ID of instance: usb); 4=ALT4 (Select mux mode: ALT4 mux port: LPI2C1_SCLS of instance: lpi2c1); 5=ALT5 (Select mux mode: ALT5 mux port: GPIO1_IO00 of instance: gpio1); 6=ALT6 (Select mux mode: ALT6 mux port: USDHC1_RESET_B of instance: usdhc1); 7=ALT7 (Select mux mode: ALT7 mux port: LPSPI3_SCK of instance: lpspi3)
0xC0 SW_MUX_CTL_PAD_GPIO_AD_B0_01 reset 0x5 — SW_MUX_CTL_PAD_GPIO_AD_B0_01 SW MUX Control Register
  [4] SION — Software Input On Field.
    0=DISABLED (Input Path is determined by functionality); 1=ENABLED (Force input path of pad GPIO_AD_B0_01)
  [2:0] MUX_MODE — MUX Mode Select Field.
    0=ALT0 (Select mux mode: ALT0 mux port: FLEXPWM2_PWMB03 of instance: flexpwm2); 1=ALT1 (Select mux mode: ALT1 mux port: XBAR1_INOUT15 of instance: xbar1); 2=ALT2 (Select mux mode: ALT2 mux port: REF_CLK_24M of instance: anatop); 3=ALT3 (Select mux mode: ALT3 mux port: USB_OTG1_ID of instance: anatop); 4=ALT4 (Select mux mode: ALT4 mux port: LPI2C1_SDAS of instance: lpi2c1); 5=ALT5 (Select mux mode: ALT5 mux port: GPIO1_IO01 of instance: gpio1); 6=ALT6 (Select mux mode: ALT6 mux port: EWM_OUT_B of instance: ewm); 7=ALT7 (Select mux mode: ALT7 mux port: LPSPI3_SDO of instance: lpspi3)
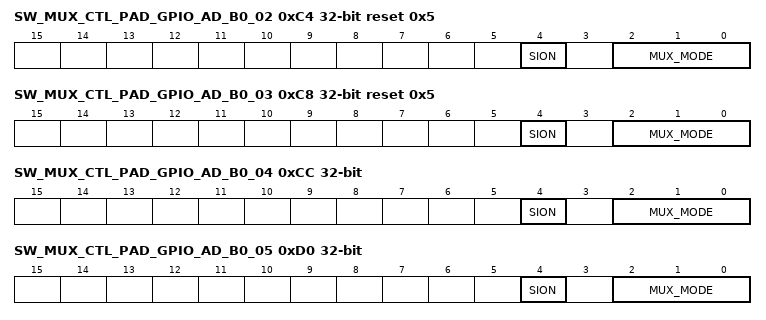
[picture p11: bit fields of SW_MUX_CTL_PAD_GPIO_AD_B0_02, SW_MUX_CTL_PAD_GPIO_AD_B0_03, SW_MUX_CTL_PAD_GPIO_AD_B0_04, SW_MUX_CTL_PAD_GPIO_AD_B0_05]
0xC4 SW_MUX_CTL_PAD_GPIO_AD_B0_02 reset 0x5 — SW_MUX_CTL_PAD_GPIO_AD_B0_02 SW MUX Control Register
  [4] SION — Software Input On Field.
    0=DISABLED (Input Path is determined by functionality); 1=ENABLED (Force input path of pad GPIO_AD_B0_02)
  [2:0] MUX_MODE — MUX Mode Select Field.
    0=ALT0 (Select mux mode: ALT0 mux port: FLEXCAN2_TX of instance: flexcan2); 1=ALT1 (Select mux mode: ALT1 mux port: XBAR1_INOUT16 of instance: xbar1); 2=ALT2 (Select mux mode: ALT2 mux port: LPUART6_TX of instance: lpuart6); 3=ALT3 (Select mux mode: ALT3 mux port: USB_OTG1_PWR of instance: usb); 4=ALT4 (Select mux mode: ALT4 mux port: FLEXPWM1_PWMX00 of instance: flexpwm1); 5=ALT5 (Select mux mode: ALT5 mux port: GPIO1_IO02 of instance: gpio1); 6=ALT6 (Select mux mode: ALT6 mux port: LPI2C1_HREQ of instance: lpi2c1); 7=ALT7 (Select mux mode: ALT7 mux port: LPSPI3_SDI of instance: lpspi3)
0xC8 SW_MUX_CTL_PAD_GPIO_AD_B0_03 reset 0x5 — SW_MUX_CTL_PAD_GPIO_AD_B0_03 SW MUX Control Register
  [4] SION — Software Input On Field.
    0=DISABLED (Input Path is determined by functionality); 1=ENABLED (Force input path of pad GPIO_AD_B0_03)
  [2:0] MUX_MODE — MUX Mode Select Field.
    0=ALT0 (Select mux mode: ALT0 mux port: FLEXCAN2_RX of instance: flexcan2); 1=ALT1 (Select mux mode: ALT1 mux port: XBAR1_INOUT17 of instance: xbar1); 2=ALT2 (Select mux mode: ALT2 mux port: LPUART6_RX of instance: lpuart6); 3=ALT3 (Select mux mode: ALT3 mux port: USB_OTG1_OC of instance: usb); 4=ALT4 (Select mux mode: ALT4 mux port: FLEXPWM1_PWMX01 of instance: flexpwm1); 5=ALT5 (Select mux mode: ALT5 mux port: GPIO1_IO03 of instance: gpio1); 6=ALT6 (Select mux mode: ALT6 mux port: REF_CLK_24M of instance: anatop); 7=ALT7 (Select mux mode: ALT7 mux port: LPSPI3_PCS0 of instance: lpspi3)
0xCC SW_MUX_CTL_PAD_GPIO_AD_B0_04 — SW_MUX_CTL_PAD_GPIO_AD_B0_04 SW MUX Control Register
  [4] SION — Software Input On Field.
    0=DISABLED (Input Path is determined by functionality); 1=ENABLED (Force input path of pad GPIO_AD_B0_04)
  [2:0] MUX_MODE — MUX Mode Select Field.
    0=ALT0 (Select mux mode: ALT0 mux port: SRC_BOOT_MODE00 of instance: src); 1=ALT1 (Select mux mode: ALT1 mux port: MQS_RIGHT of instance: mqs); 2=ALT2 (Select mux mode: ALT2 mux port: ENET_TX_DATA03 of instance: enet); 3=ALT3 (Select mux mode: ALT3 mux port: SAI2_TX_SYNC of instance: sai2); 4=ALT4 (Select mux mode: ALT4 mux port: CSI_DATA09 of instance: csi); 5=ALT5 (Select mux mode: ALT5 mux port: GPIO1_IO04 of instance: gpio1); 6=ALT6 (Select mux mode: ALT6 mux port: PIT_TRIGGER00 of instance: pit); 7=ALT7 (Select mux mode: ALT7 mux port: LPSPI3_PCS1 of instance: lpspi3)
0xD0 SW_MUX_CTL_PAD_GPIO_AD_B0_05 — SW_MUX_CTL_PAD_GPIO_AD_B0_05 SW MUX Control Register
  [4] SION — Software Input On Field.
    0=DISABLED (Input Path is determined by functionality); 1=ENABLED (Force input path of pad GPIO_AD_B0_05)
  [2:0] MUX_MODE — MUX Mode Select Field.
    0=ALT0 (Select mux mode: ALT0 mux port: SRC_BOOT_MODE01 of instance: src); 1=ALT1 (Select mux mode: ALT1 mux port: MQS_LEFT of instance: mqs); 2=ALT2 (Select mux mode: ALT2 mux port: ENET_TX_DATA02 of instance: enet); 3=ALT3 (Select mux mode: ALT3 mux port: SAI2_TX_BCLK of instance: sai2); 4=ALT4 (Select mux mode: ALT4 mux port: CSI_DATA08 of instance: csi); 5=ALT5 (Select mux mode: ALT5 mux port: GPIO1_IO05 of instance: gpio1); 6=ALT6 (Select mux mode: ALT6 mux port: XBAR1_INOUT17 of instance: xbar1); 7=ALT7 (Select mux mode: ALT7 mux port: LPSPI3_PCS2 of instance: lpspi3)
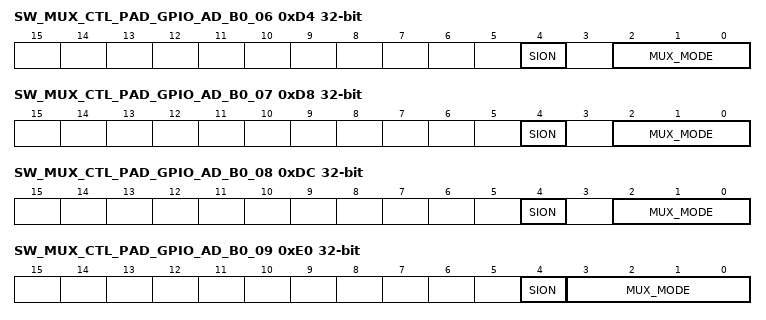
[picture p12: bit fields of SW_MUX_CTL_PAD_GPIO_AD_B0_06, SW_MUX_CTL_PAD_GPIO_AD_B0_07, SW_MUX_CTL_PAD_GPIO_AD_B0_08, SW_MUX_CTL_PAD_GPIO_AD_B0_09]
0xD4 SW_MUX_CTL_PAD_GPIO_AD_B0_06 — SW_MUX_CTL_PAD_GPIO_AD_B0_06 SW MUX Control Register
  [4] SION — Software Input On Field.
    0=DISABLED (Input Path is determined by functionality); 1=ENABLED (Force input path of pad GPIO_AD_B0_06)
  [2:0] MUX_MODE — MUX Mode Select Field.
    0=ALT0 (Select mux mode: ALT0 mux port: JTAG_TMS of instance: jtag_mux); 1=ALT1 (Select mux mode: ALT1 mux port: GPT2_COMPARE1 of instance: gpt2); 2=ALT2 (Select mux mode: ALT2 mux port: ENET_RX_CLK of instance: enet); 3=ALT3 (Select mux mode: ALT3 mux port: SAI2_RX_BCLK of instance: sai2); 4=ALT4 (Select mux mode: ALT4 mux port: CSI_DATA07 of instance: csi); 5=ALT5 (Select mux mode: ALT5 mux port: GPIO1_IO06 of instance: gpio1); 6=ALT6 (Select mux mode: ALT6 mux port: XBAR1_INOUT18 of instance: xbar1); 7=ALT7 (Select mux mode: ALT7 mux port: LPSPI3_PCS3 of instance: lpspi3)
0xD8 SW_MUX_CTL_PAD_GPIO_AD_B0_07 — SW_MUX_CTL_PAD_GPIO_AD_B0_07 SW MUX Control Register
  [4] SION — Software Input On Field.
    0=DISABLED (Input Path is determined by functionality); 1=ENABLED (Force input path of pad GPIO_AD_B0_07)
  [2:0] MUX_MODE — MUX Mode Select Field.
    0=ALT0 (Select mux mode: ALT0 mux port: JTAG_TCK of instance: jtag_mux); 1=ALT1 (Select mux mode: ALT1 mux port: GPT2_COMPARE2 of instance: gpt2); 2=ALT2 (Select mux mode: ALT2 mux port: ENET_TX_ER of instance: enet); 3=ALT3 (Select mux mode: ALT3 mux port: SAI2_RX_SYNC of instance: sai2); 4=ALT4 (Select mux mode: ALT4 mux port: CSI_DATA06 of instance: csi); 5=ALT5 (Select mux mode: ALT5 mux port: GPIO1_IO07 of instance: gpio1); 6=ALT6 (Select mux mode: ALT6 mux port: XBAR1_INOUT19 of instance: xbar1); 7=ALT7 (Select mux mode: ALT7 mux port: ENET_1588_EVENT3_OUT of instance: enet)
0xDC SW_MUX_CTL_PAD_GPIO_AD_B0_08 — SW_MUX_CTL_PAD_GPIO_AD_B0_08 SW MUX Control Register
  [4] SION — Software Input On Field.
    0=DISABLED (Input Path is determined by functionality); 1=ENABLED (Force input path of pad GPIO_AD_B0_08)
  [2:0] MUX_MODE — MUX Mode Select Field.
    0=ALT0 (Select mux mode: ALT0 mux port: JTAG_MOD of instance: jtag_mux); 1=ALT1 (Select mux mode: ALT1 mux port: GPT2_COMPARE3 of instance: gpt2); 2=ALT2 (Select mux mode: ALT2 mux port: ENET_RX_DATA03 of instance: enet); 3=ALT3 (Select mux mode: ALT3 mux port: SAI2_RX_DATA of instance: sai2); 4=ALT4 (Select mux mode: ALT4 mux port: CSI_DATA05 of instance: csi); 5=ALT5 (Select mux mode: ALT5 mux port: GPIO1_IO08 of instance: gpio1); 6=ALT6 (Select mux mode: ALT6 mux port: XBAR1_IN20 of instance: xbar1); 7=ALT7 (Select mux mode: ALT7 mux port: ENET_1588_EVENT3_IN of instance: enet)
0xE0 SW_MUX_CTL_PAD_GPIO_AD_B0_09 — SW_MUX_CTL_PAD_GPIO_AD_B0_09 SW MUX Control Register
  [4] SION — Software Input On Field.
    0=DISABLED (Input Path is determined by functionality); 1=ENABLED (Force input path of pad GPIO_AD_B0_09)
  [3:0] MUX_MODE — MUX Mode Select Field.
    0=ALT0 (Select mux mode: ALT0 mux port: JTAG_TDI of instance: jtag_mux); 1=ALT1 (Select mux mode: ALT1 mux port: FLEXPWM2_PWMA03 of instance: flexpwm2); 2=ALT2 (Select mux mode: ALT2 mux port: ENET_RX_DATA02 of instance: enet); 3=ALT3 (Select mux mode: ALT3 mux port: SAI2_TX_DATA of instance: sai2); 4=ALT4 (Select mux mode: ALT4 mux port: CSI_DATA04 of instance: csi); 5=ALT5 (Select mux mode: ALT5 mux port: GPIO1_IO09 of instance: gpio1); 6=ALT6 (Select mux mode: ALT6 mux port: XBAR1_IN21 of instance: xbar1); 7=ALT7 (Select mux mode: ALT7 mux port: GPT2_CLK of instance: gpt2); 9=ALT9 (Select mux mode: ALT9 mux port: SEMC_DQS4 of instance: semc)
